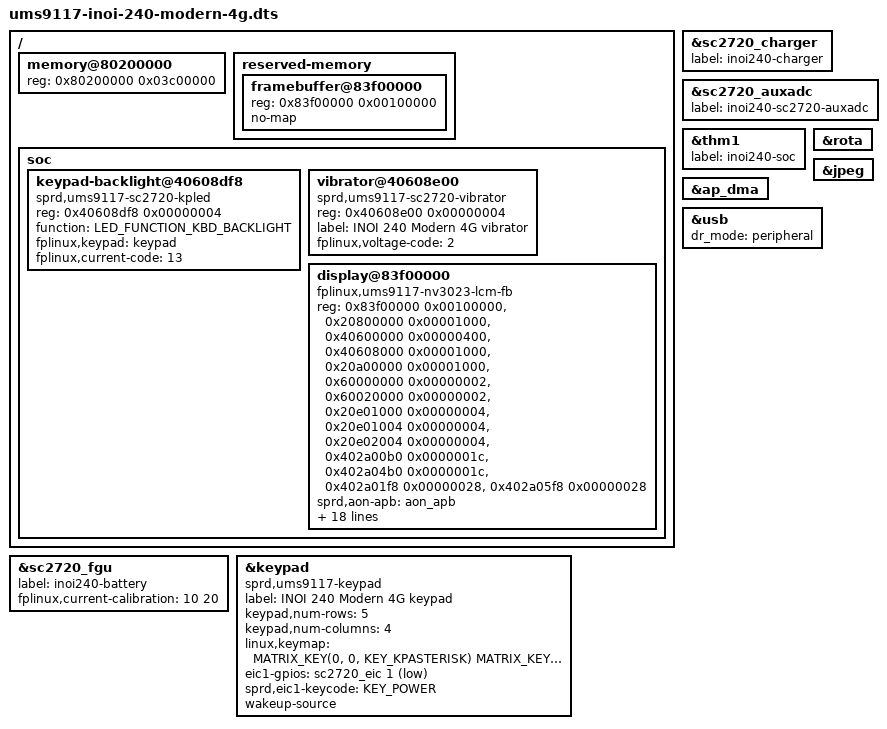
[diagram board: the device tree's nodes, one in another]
// SPDX-License-Identifier: GPL-2.0-only
/dts-v1/;

#include <dt-bindings/input/input.h>
#include <dt-bindings/gpio/gpio.h>
#include <dt-bindings/leds/common.h>
#include "ums9117.dtsi"
#include "ums9117-sc2720.dtsi"
#include "fplinux-target-identity.dtsi"
#include "inoi-240-modern-4g-nand-readonly.dtsi"
#include "inoi-240-modern-4g-bluetooth.dtsi"
#include "inoi-240-modern-4g-microsd.dtsi"

/ {
	memory@80200000 {
		device_type = "memory";
		reg = <0x80200000 0x03c00000>;
	};

	reserved-memory {
		#address-cells = <1>;
		#size-cells = <1>;
		ranges;

		framebuffer@83f00000 {
			reg = <0x83f00000 0x00100000>;
			no-map;
		};
	};

	soc {
		keypad-backlight@40608df8 {
			compatible = "sprd,ums9117-sc2720-kpled";
			reg = <0x40608df8 0x00000004>;
			function = LED_FUNCTION_KBD_BACKLIGHT;
			fplinux,keypad = <&keypad>;
			fplinux,current-code = <13>;
		};

		vibrator@40608e00 {
			compatible = "sprd,ums9117-sc2720-vibrator";
			reg = <0x40608e00 0x00000004>;
			label = "INOI 240 Modern 4G vibrator";
			fplinux,voltage-code = <2>;
		};

		display@83f00000 {
			compatible = "fplinux,ums9117-nv3023-lcm-fb";
			reg = <0x83f00000 0x00100000>,
			      <0x20800000 0x00001000>,
			      <0x40600000 0x00000400>,
			      <0x40608000 0x00001000>,
			      <0x20a00000 0x00001000>,
			      <0x60000000 0x00000002>,
			      <0x60020000 0x00000002>,
			      <0x20e01000 0x00000004>,
			      <0x20e01004 0x00000004>,
			      <0x20e02004 0x00000004>,
			      <0x402a00b0 0x0000001c>,
			      <0x402a04b0 0x0000001c>,
			      <0x402a01f8 0x00000028>,
			      <0x402a05f8 0x00000028>;
			reg-names = "framebuffer", "lcdc", "adi-controller",
				    "analog-slave", "lcm", "lcm-command", "lcm-data",
				    "ap-ahb-gate-set", "ap-ahb-reset-set",
				    "ap-ahb-reset-clear", "pinmux", "pinconf",
				    "pinmux-data", "pinconf-data";
			sprd,aon-apb = <&aon_apb>;
			/* fpdoom cmd3025_inoi MCU timing at the 128 MHz AHB clock. */
			sprd,dbi-timing-ns = <50 55 110 20 70 35>;
			/* LCM control pins. */
			sprd,pinmux-offsets = <
				0x000 0x004 0x008 0x00c 0x010 0x014 0x018
			>;
			sprd,pinmux-values = <
				0 0 0x10 0x10 0x10 0x10 0x10
			>;
			sprd,pinconf-offsets = <
				0x000 0x004 0x008 0x00c 0x010 0x014 0x018
			>;
			sprd,pinconf-values = <
				0x00182001 0x00182046 0x00182001
				0x00182004 0x00182004 0x00182004 0x00182004
			>;
			/* Ten DBI data pins, separate from the intervening peripherals. */
			sprd,pinmux-data-offsets = <
				0x00 0x04 0x08 0x0c 0x10 0x14 0x18 0x1c 0x20 0x24
			>;
			sprd,pinmux-data-values = <
				0x10 0x10 0x10 0x10 0x10
				0x10 0x10 0x10 0x10 0x10
			>;
			sprd,pinconf-data-offsets = <
				0x00 0x04 0x08 0x0c 0x10 0x14 0x18 0x1c 0x20 0x24
			>;
			sprd,pinconf-data-values = <
				0x00182004 0x00182004 0x00182004 0x00182004 0x00182004
				0x00182004 0x00182004 0x00182004 0x00182004 0x00182004
			>;
			/* INOI uses RGB WLED channels only; the W channel stays dark. */
			sprd,wled-current-levels = <31 31 31 0>;
		};
	};
};

#include "ums9117-ram-session.dtsi"

&sc2720_charger {
	label = "inoi240-charger";
};

&sc2720_fgu {
	label = "inoi240-battery";
	fplinux,current-calibration = <10 20>;
};

&sc2720_auxadc {
	label = "inoi240-sc2720-auxadc";
};

&thm1 {
	status = "okay";
	label = "inoi240-soc";
};

&ap_dma {
	status = "okay";
};

&rota {
	status = "okay";
};

&jpeg {
	status = "okay";
};

&keypad {
	compatible = "sprd,ums9117-keypad";
	status = "okay";
	label = "INOI 240 Modern 4G keypad";
	keypad,num-rows = <5>;
	keypad,num-columns = <4>;
	linux,keymap = <
		MATRIX_KEY(0, 0, KEY_KPASTERISK) /* * */
		MATRIX_KEY(0, 1, KEY_0)
		MATRIX_KEY(0, 2, KEY_KPDOT) /* # */
		MATRIX_KEY(0, 3, KEY_ENTER) /* centre */
		MATRIX_KEY(1, 0, KEY_7)
		MATRIX_KEY(1, 1, KEY_8)
		MATRIX_KEY(1, 2, KEY_9)
		MATRIX_KEY(1, 3, KEY_LEFT)
		MATRIX_KEY(2, 0, KEY_4)
		MATRIX_KEY(2, 1, KEY_5)
		MATRIX_KEY(2, 2, KEY_6)
		MATRIX_KEY(2, 3, KEY_RIGHT)
		MATRIX_KEY(3, 0, KEY_1)
		MATRIX_KEY(3, 1, KEY_2)
		MATRIX_KEY(3, 2, KEY_3)
		MATRIX_KEY(3, 3, KEY_DOWN)
		MATRIX_KEY(4, 0, KEY_TAB) /* left soft */
		MATRIX_KEY(4, 1, KEY_ENTER) /* dial */
		MATRIX_KEY(4, 2, KEY_BACKSPACE) /* right soft */
		MATRIX_KEY(4, 3, KEY_UP)
	>;
	eic1-gpios = <&sc2720_eic 1 GPIO_ACTIVE_LOW>;
	sprd,eic1-keycode = <KEY_POWER>;
	wakeup-source;
};

&usb {
	dr_mode = "peripheral";
	status = "okay";
};
